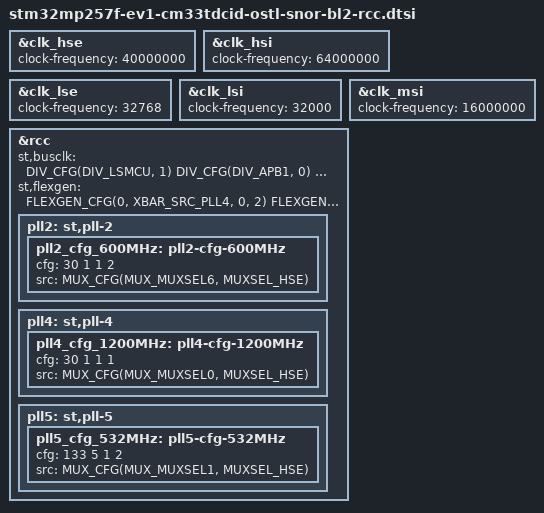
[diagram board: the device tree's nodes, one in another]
// SPDX-License-Identifier: (GPL-2.0-only OR BSD-3-Clause)
/*
 * Copyright (C) STMicroelectronics 2022 - All Rights Reserved
 * Author: Loic Pallardy loic.pallardy@foss.st.com for STMicroelectronics.
 */

/*
 * stm32mp257f Clock tree device tree configuration
 * Project : ostl
 * Generated by XLmx tool version 2.8 - 2/28/2025 4:09:35 PM
 */

&clk_hse {
	clock-frequency = <40000000>;
};

&clk_hsi {
	clock-frequency = <64000000>;
};

&clk_lse {
	clock-frequency = <32768>;
};

&clk_lsi {
	clock-frequency = <32000>;
};

&clk_msi {
	clock-frequency = <16000000>;
};

&rcc {
	st,busclk = <
		DIV_CFG(DIV_LSMCU, 1)
		DIV_CFG(DIV_APB1, 0)
		DIV_CFG(DIV_APB2, 0)
		DIV_CFG(DIV_APB3, 0)
		DIV_CFG(DIV_APB4, 0)
		DIV_CFG(DIV_APBDBG, 0)
	>;

	st,flexgen = <
		FLEXGEN_CFG(0, XBAR_SRC_PLL4, 0, 2)
		FLEXGEN_CFG(1, XBAR_SRC_PLL4, 0, 5)
		FLEXGEN_CFG(2, XBAR_SRC_PLL4, 0, 1)
		FLEXGEN_CFG(5, XBAR_SRC_PLL4, 0, 2)
		FLEXGEN_CFG(9, XBAR_SRC_HSI_KER, 0, 0)
		FLEXGEN_CFG(15, XBAR_SRC_PLL4, 0, 11)
		FLEXGEN_CFG(49, XBAR_SRC_PLL5, 0, 3)
	>;


	pll2: st,pll-2 {
		pll2_cfg_600MHz: pll2-cfg-600MHz {
			cfg = <30 1 1 2>;
			src = <MUX_CFG(MUX_MUXSEL6, MUXSEL_HSE)>;
		};
	};

	pll4: st,pll-4 {
		pll4_cfg_1200MHz: pll4-cfg-1200MHz {
			cfg = <30 1 1 1>;
			src = <MUX_CFG(MUX_MUXSEL0, MUXSEL_HSE)>;
		};
	};

	pll5: st,pll-5 {
		pll5_cfg_532MHz: pll5-cfg-532MHz {
			cfg = <133 5 1 2>;
			src = <MUX_CFG(MUX_MUXSEL1, MUXSEL_HSE)>;
		};
	};
};
